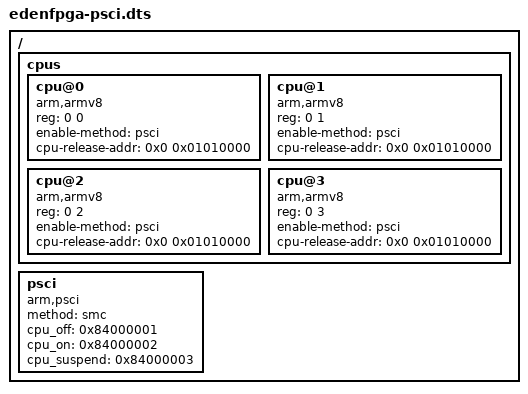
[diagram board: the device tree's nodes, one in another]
/*
 * Eden FPGA Board With PSCI Support
 */

#include "edenfpga.dts"

/ {
	cpus {
		#address-cells = <2>;
		#size-cells = <0>;

		cpu@0 {
			device_type = "cpu";
			compatible = "arm,armv8";
			reg = <0 0>;
			enable-method = "psci";
			cpu-release-addr = <0x0 0x01010000>;
		};
		cpu@1 {
			device_type = "cpu";
			compatible = "arm,armv8";
			reg = <0 1>;
			enable-method = "psci";
			cpu-release-addr = <0x0 0x01010000>;
		};
		cpu@2 {
			device_type = "cpu";
			compatible = "arm,armv8";
			reg = <0 2>;
			enable-method = "psci";
			cpu-release-addr = <0x0 0x01010000>;
		};
		cpu@3 {
			device_type = "cpu";
			compatible = "arm,armv8";
			reg = <0 3>;
			enable-method = "psci";
			cpu-release-addr = <0x0 0x01010000>;
		};
	};

	psci {
		compatible      = "arm,psci";
		method          = "smc";
		cpu_off		= <0x84000001>;
		cpu_on		= <0x84000002>;
		cpu_suspend     = <0x84000003>;
	};
};
